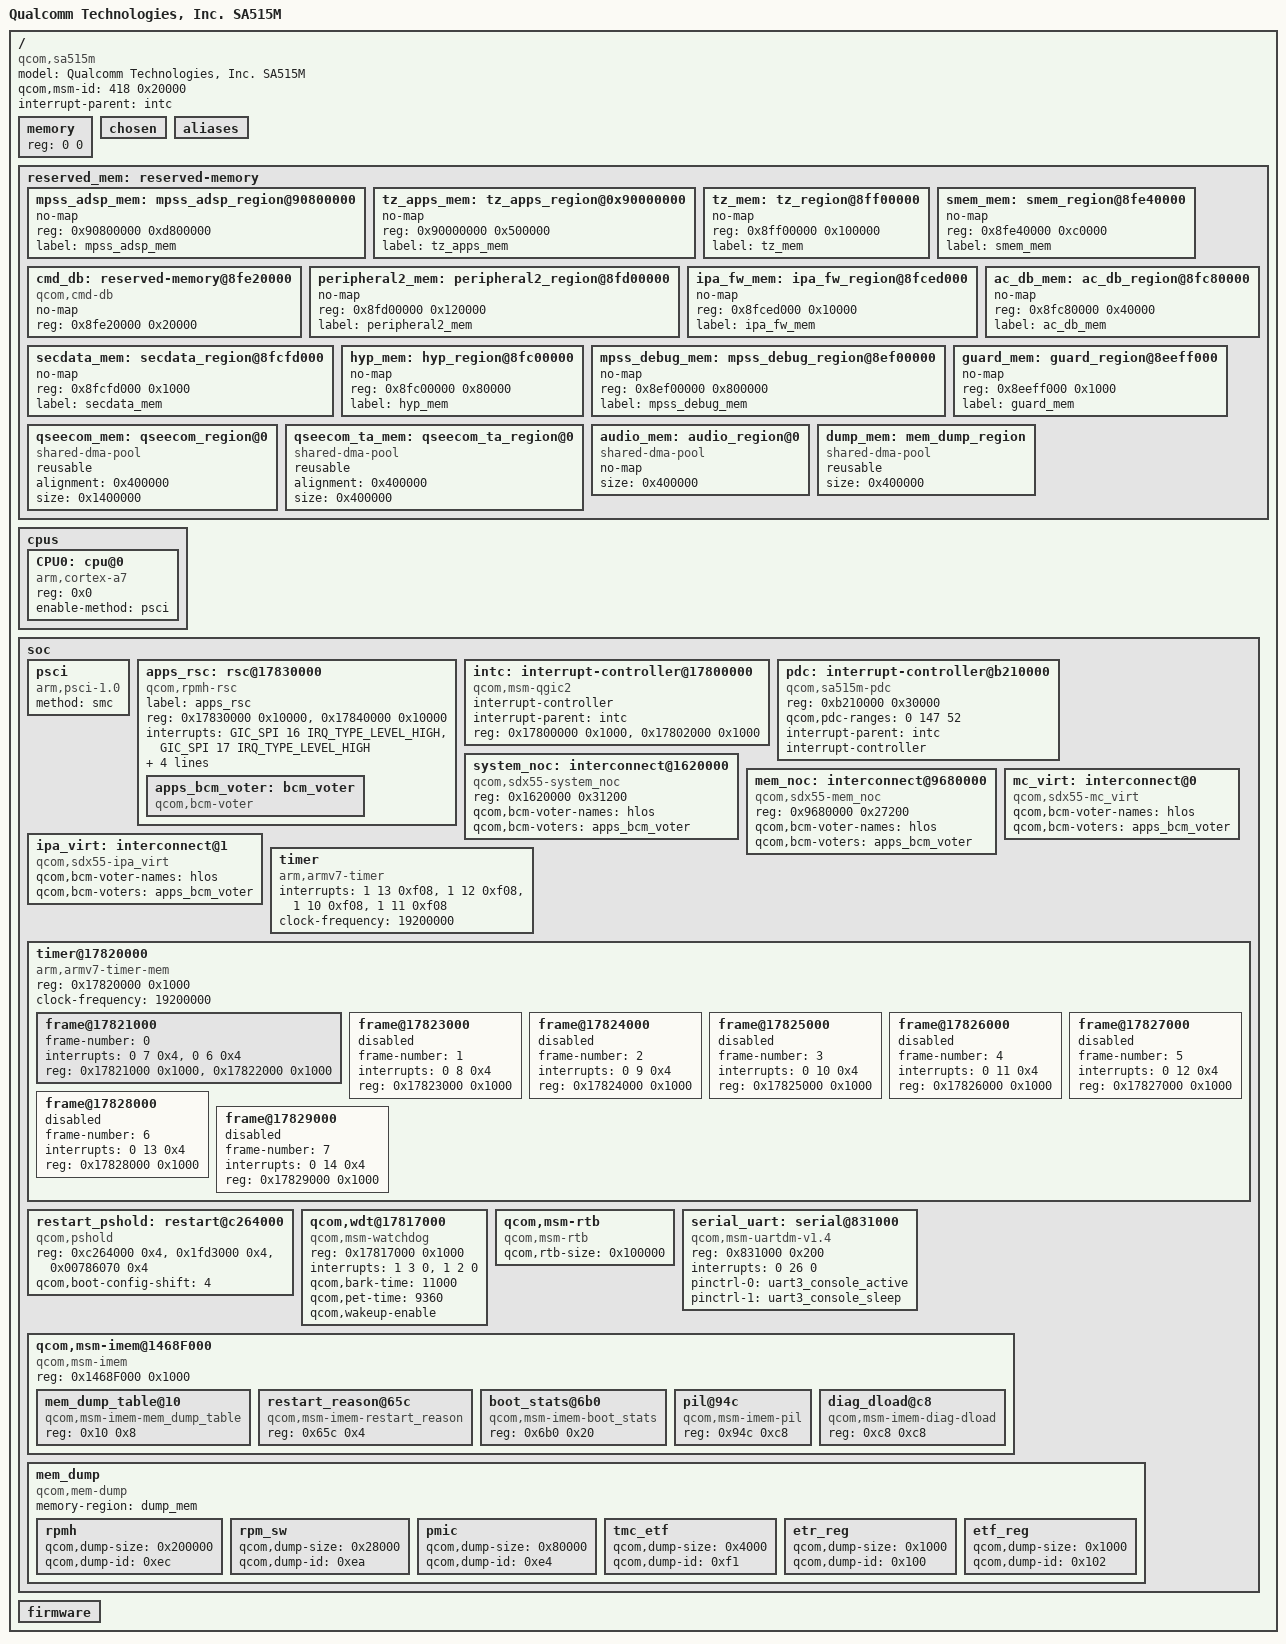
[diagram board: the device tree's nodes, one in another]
#include <dt-bindings/interconnect/qcom,icc.h>
#include <dt-bindings/interconnect/qcom,sdx55.h>
#include <dt-bindings/interrupt-controller/arm-gic.h>
#include <dt-bindings/soc/qcom,rpmh-rsc.h>

/ {
	#address-cells = <1>;
	#size-cells = <1>;
	model = "Qualcomm Technologies, Inc. SA515M";
	compatible = "qcom,sa515m";
	qcom,msm-id = <418 0x20000>;

	interrupt-parent = <&intc>;

	memory { device_type = "memory"; reg = <0 0>; };

	chosen: chosen { };

	aliases {
	};

	reserved_mem: reserved-memory {
		#address-cells = <1>;
		#size-cells = <1>;
		ranges;

		mpss_adsp_mem: mpss_adsp_region@90800000 {
			no-map;
			reg = <0x90800000 0xd800000>;
			label = "mpss_adsp_mem";
		};

		tz_apps_mem: tz_apps_region@0x90000000 {
			no-map;
			reg = <0x90000000 0x500000>;
			label = "tz_apps_mem";
		};

		tz_mem: tz_region@8ff00000 {
			no-map;
			reg = <0x8ff00000 0x100000>;
			label = "tz_mem";
		};

		smem_mem: smem_region@8fe40000 {
			no-map;
			reg = <0x8fe40000 0xc0000>;
			label = "smem_mem";
		};

		cmd_db: reserved-memory@8fe20000 {
			compatible = "qcom,cmd-db";
			no-map;
			reg = <0x8fe20000 0x20000>;
		};

		peripheral2_mem: peripheral2_region@8fd00000 {
			no-map;
			reg = <0x8fd00000 0x120000>;
			label = "peripheral2_mem";
		};

		ipa_fw_mem: ipa_fw_region@8fced000 {
			no-map;
			reg = <0x8fced000 0x10000>;
			label = "ipa_fw_mem";
		};

		secdata_mem: secdata_region@8fcfd000 {
			no-map;
			reg = <0x8fcfd000 0x1000>;
			label = "secdata_mem";
		};

		ac_db_mem: ac_db_region@8fc80000 {
			no-map;
			reg = <0x8fc80000 0x40000>;
			label = "ac_db_mem";
		};

		hyp_mem: hyp_region@8fc00000 {
			no-map;
			reg = <0x8fc00000 0x80000>;
			label = "hyp_mem";
		};

		mpss_debug_mem: mpss_debug_region@8ef00000 {
			no-map;
			reg = <0x8ef00000 0x800000>;
			label = "mpss_debug_mem";
		};

		guard_mem: guard_region@8eeff000 {
			no-map;
			reg = <0x8eeff000 0x1000>;
			label = "guard_mem";
		};

		qseecom_mem: qseecom_region@0 {
			compatible = "shared-dma-pool";
			reusable;
			alignment = <0x400000>;
			size = <0x1400000>;
		};

		qseecom_ta_mem: qseecom_ta_region@0 {
			compatible = "shared-dma-pool";
			reusable;
			alignment = <0x400000>;
			size = <0x400000>;
		};

		audio_mem: audio_region@0 {
			compatible = "shared-dma-pool";
			no-map;
			size = <0x400000>;
		};

		dump_mem: mem_dump_region {
			compatible = "shared-dma-pool";
			reusable;
			size = <0x400000>;
		};
	};

	cpus {
		#size-cells = <0>;
		#address-cells = <1>;

		CPU0: cpu@0 {
			device_type = "cpu";
			compatible = "arm,cortex-a7";
			reg = <0x0>;
			enable-method = "psci";
			#cooling-cells = <2>;
		};
	};

	soc: soc { };

	firmware: firmware {};
};

&soc {
	#address-cells = <1>;
	#size-cells = <1>;
	ranges;

	psci {
		compatible = "arm,psci-1.0";
		method = "smc";
	};

	apps_rsc: rsc@17830000 {
		label = "apps_rsc";
		compatible = "qcom,rpmh-rsc";
		reg = <0x17830000 0x10000>,
		      <0x17840000 0x10000>;
		reg-names = "drv-0", "drv-1";
		interrupts = <GIC_SPI 16 IRQ_TYPE_LEVEL_HIGH>,
			     <GIC_SPI 17 IRQ_TYPE_LEVEL_HIGH>;
		qcom,tcs-offset = <0xd00>;
		qcom,drv-id = <1>;
		qcom,tcs-config = <ACTIVE_TCS  2>,
				  <SLEEP_TCS   2>,
				  <WAKE_TCS    2>,
				  <CONTROL_TCS 1>;

		apps_bcm_voter: bcm_voter {
			compatible = "qcom,bcm-voter";
		};
	};

	intc: interrupt-controller@17800000 {
		compatible = "qcom,msm-qgic2";
		interrupt-controller;
		interrupt-parent = <&intc>;
		#interrupt-cells = <3>;
		reg = <0x17800000 0x1000>,
		      <0x17802000 0x1000>;
	};

	pdc: interrupt-controller@b210000 {
		compatible = "qcom,sa515m-pdc";
		reg = <0xb210000 0x30000>;
		qcom,pdc-ranges = <0 147 52>;
		#interrupt-cells = <3>;
		interrupt-parent = <&intc>;
		interrupt-controller;
	};

	system_noc: interconnect@1620000 {
		compatible = "qcom,sdx55-system_noc";
		reg = <0x1620000 0x31200>;
		#interconnect-cells = <1>;
		qcom,bcm-voter-names = "hlos";
		qcom,bcm-voters = <&apps_bcm_voter>;
	};

	mem_noc: interconnect@9680000 {
		compatible = "qcom,sdx55-mem_noc";
		reg = <0x9680000 0x27200>;
		#interconnect-cells = <1>;
		qcom,bcm-voter-names = "hlos";
		qcom,bcm-voters = <&apps_bcm_voter>;
	};

	mc_virt: interconnect@0 {
		compatible = "qcom,sdx55-mc_virt";
		#interconnect-cells = <1>;
		qcom,bcm-voter-names = "hlos";
		qcom,bcm-voters = <&apps_bcm_voter>;
	};

	ipa_virt: interconnect@1 {
		compatible = "qcom,sdx55-ipa_virt";
		#interconnect-cells = <1>;
		qcom,bcm-voter-names = "hlos";
		qcom,bcm-voters = <&apps_bcm_voter>;
	};

	timer {
		compatible = "arm,armv7-timer";
		interrupts = <1 13 0xf08>,
			<1 12 0xf08>,
			<1 10 0xf08>,
			<1 11 0xf08>;
		clock-frequency = <19200000>;
	};

	timer@17820000 {
		#address-cells = <1>;
		#size-cells = <1>;
		ranges;
		compatible = "arm,armv7-timer-mem";
		reg = <0x17820000 0x1000>;
		clock-frequency = <19200000>;

		frame@17821000 {
			frame-number = <0>;
			interrupts = <0 7 0x4>,
				     <0 6 0x4>;
			reg = <0x17821000 0x1000>,
			      <0x17822000 0x1000>;
		};

		frame@17823000 {
			frame-number = <1>;
			interrupts = <0 8 0x4>;
			reg = <0x17823000 0x1000>;
			status = "disabled";
		};

		frame@17824000 {
			frame-number = <2>;
			interrupts = <0 9 0x4>;
			reg = <0x17824000 0x1000>;
			status = "disabled";
		};

		frame@17825000 {
			frame-number = <3>;
			interrupts = <0 10 0x4>;
			reg = <0x17825000 0x1000>;
			status = "disabled";
		};

		frame@17826000 {
			frame-number = <4>;
			interrupts = <0 11 0x4>;
			reg = <0x17826000 0x1000>;
			status = "disabled";
		};

		frame@17827000 {
			frame-number = <5>;
			interrupts = <0 12 0x4>;
			reg = <0x17827000 0x1000>;
			status = "disabled";
		};

		frame@17828000 {
			frame-number = <6>;
			interrupts = <0 13 0x4>;
			reg = <0x17828000 0x1000>;
			status = "disabled";
		};

		frame@17829000 {
			frame-number = <7>;
			interrupts = <0 14 0x4>;
			reg = <0x17829000 0x1000>;
			status = "disabled";
		};
	};

	restart_pshold: restart@c264000 {
		compatible = "qcom,pshold";
		reg = <0xc264000 0x4>,
		      <0x1fd3000 0x4>,
		      <0x00786070 0x4>;
		reg-names = "pshold-base", "tcsr-boot-misc-detect",
				"boot-config";
		qcom,boot-config-shift = <4>;
	};

	qcom,wdt@17817000 {
		compatible = "qcom,msm-watchdog";
		reg = <0x17817000 0x1000>;
		reg-names = "wdt-base";
		interrupts = <1 3 0>, <1 2 0>;
		qcom,bark-time = <11000>;
		qcom,pet-time = <9360>;
		qcom,wakeup-enable;
	};

	qcom,msm-rtb {
		compatible = "qcom,msm-rtb";
		qcom,rtb-size = <0x100000>;
	};

	serial_uart: serial@831000 {
		compatible = "qcom,msm-uartdm-v1.4", "qcom,msm-uartdm";
		reg = <0x831000 0x200>;
		interrupts = <0 26 0>;
		pinctrl-names = "default", "sleep";
		pinctrl-0 = <&uart3_console_active>;
		pinctrl-1 = <&uart3_console_sleep>;
		status = "ok";
	};

	qcom,msm-imem@1468F000 {
		compatible = "qcom,msm-imem";
		reg = <0x1468F000 0x1000>; /* Address and size of IMEM */
		ranges = <0x0 0x1468F000 0x1000>;
		#address-cells = <1>;
		#size-cells = <1>;

		mem_dump_table@10 {
			compatible = "qcom,msm-imem-mem_dump_table";
			reg = <0x10 0x8>;
		};

		restart_reason@65c {
			compatible = "qcom,msm-imem-restart_reason";
			reg = <0x65c 0x4>;
		};

		boot_stats@6b0 {
			compatible = "qcom,msm-imem-boot_stats";
			reg = <0x6b0 0x20>;
		};

		pil@94c {
			compatible = "qcom,msm-imem-pil";
			reg = <0x94c 0xc8>;
		};

		diag_dload@c8 {
			compatible = "qcom,msm-imem-diag-dload";
			reg = <0xc8 0xc8>;
		};
	};
	mem_dump {
		compatible = "qcom,mem-dump";
		memory-region = <&dump_mem>;

		rpmh {
			qcom,dump-size = <0x200000>;
			qcom,dump-id = <0xec>;
		};

		rpm_sw {
			qcom,dump-size = <0x28000>;
			qcom,dump-id = <0xea>;
		};

		pmic {
			qcom,dump-size = <0x80000>;
			qcom,dump-id = <0xe4>;
		};


		tmc_etf {
			qcom,dump-size = <0x4000>;
			qcom,dump-id = <0xf1>;
		};

		etr_reg {
			qcom,dump-size = <0x1000>;
			qcom,dump-id = <0x100>;
		};

		etf_reg {
			qcom,dump-size = <0x1000>;
			qcom,dump-id = <0x102>;
		};
	};

};

#include "sa515m-pinctrl.dtsi"
#include "sa515m-ion.dtsi"
#include "msm-arm-smmu-sa515m.dtsi"
